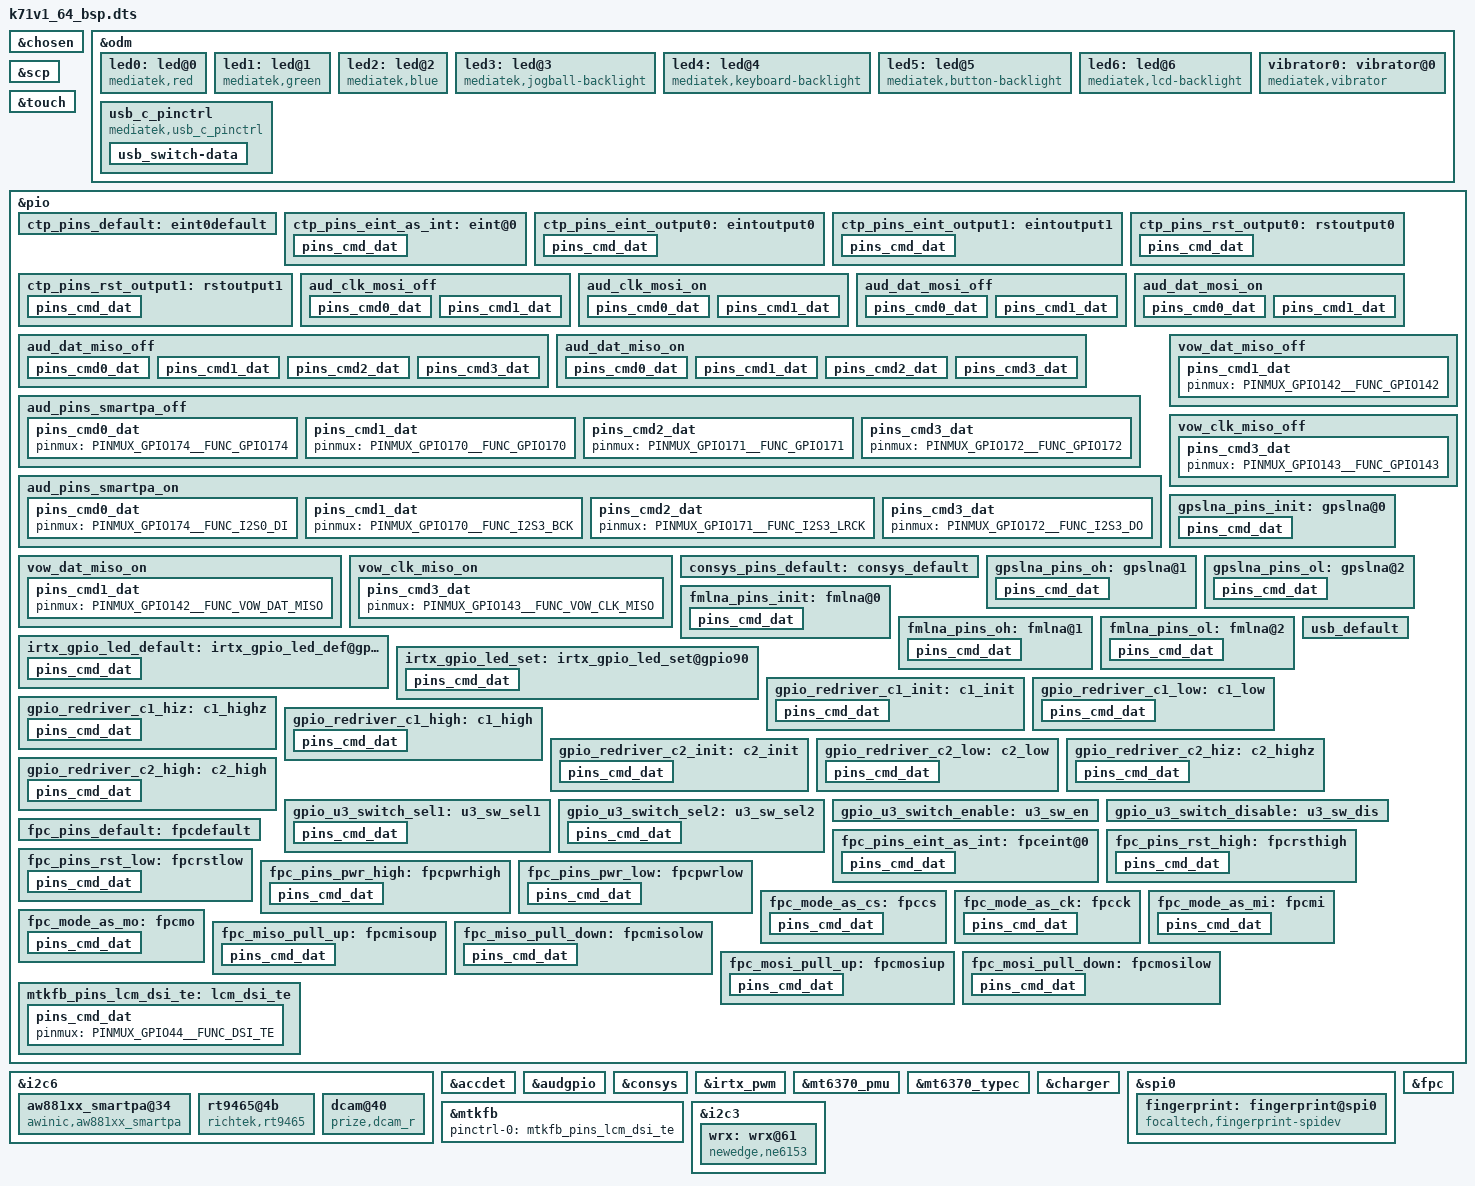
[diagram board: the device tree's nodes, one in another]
/*
 * Mediatek's mt6771 SoC device tree source
 *
 * Copyright (C) 2016 MediaTek Inc.
 *
 * This program is free software; you can redistribute it and/or modify
 * it under the terms of the GNU General Public License version 2 as
 * published by the Free Software Foundation.
 *
 * This program is distributed in the hope that it will be useful,
 * but WITHOUT ANY WARRANTY; without even the implied warranty of
 * MERCHANTABILITY or FITNESS FOR A PARTICULAR PURPOSE.
 * See http://www.gnu.org/licenses/gpl-2.0.html for more details.
 */
/dts-v1/;
/plugin/;
#include <dt-bindings/interrupt-controller/irq.h>
#include <dt-bindings/interrupt-controller/arm-gic.h>
#include <dt-bindings/pinctrl/mt6771-pinfunc.h>

/* chosen */
&chosen {
	/* fpga may has no lk, we need to specify display info here */
	/* fb buffer is reserved using this dts by memory node above */

	atag,videolfb-fb_base_l = <0x5e605000>;
	atag,videolfb-fb_base_h = <0x0>;
	atag,videolfb-islcmfound = <1>;
	atag,videolfb-islcm_inited = <0>;
	atag,videolfb-fps= <6000>;
	atag,videolfb-vramSize= <0x017bb000>;
	atag,videolfb-lcmname= "nt35595_fhd_dsi_cmd_truly_nt50358_drv";
};

&odm {
	led0:led@0 {
		compatible = "mediatek,red";
		led_mode = <0>;
		data = <1>;
		pwm_config = <0 0 0 0 0>;
	};
	led1:led@1 {
		compatible = "mediatek,green";
		led_mode = <0>;
		data = <1>;
		pwm_config = <0 0 0 0 0>;
	};
	led2:led@2 {
		compatible = "mediatek,blue";
		led_mode = <0>;
		data = <1>;
		pwm_config = <0 0 0 0 0>;
	};
	led3:led@3 {
		compatible = "mediatek,jogball-backlight";
		led_mode = <0>;
		data = <1>;
		pwm_config = <0 0 0 0 0>;
	};
	led4:led@4 {
		compatible = "mediatek,keyboard-backlight";
		led_mode = <0>;
		data = <1>;
		pwm_config = <0 0 0 0 0>;
	};
	led5:led@5 {
		compatible = "mediatek,button-backlight";
		led_mode = <0>;
		data = <1>;
		pwm_config = <0 0 0 0 0>;
	};
	led6:led@6 {
		compatible = "mediatek,lcd-backlight";
		led_mode = <5>;
		data = <1>;
		pwm_config = <0 3 0 0 0>;/*prize modify by mhy*/
	};
	vibrator0:vibrator@0 {
		compatible = "mediatek,vibrator";
		vib_timer = <25>;
		vib_limit = <9>;
		vib_vol= <11>;
	};
	usb_c_pinctrl:usb_c_pinctrl {
		compatible = "mediatek,usb_c_pinctrl";
	};
};

&scp {
	core_1 = "enable";
	scp_sramSize = <0x00080000>;     /* scp_A_sram_size */
};

/* TOUCH start */
&touch {
	tpd-resolution = <1080 2340>;/*prize modify by mhy*/
	use-tpd-button = <0>;
	tpd-key-num = <3>;
	tpd-key-local= <139 172 158 0>;
	tpd-key-dim-local = <90 883 100 40 230 883 100 40 370 883 100 40 0 0 0 0>;
	tpd-max-touch-num = <5>;
	tpd-filter-enable = <1>;
	tpd-filter-pixel-density = <146>;
	tpd-filter-custom-prameters = <0 0 0 0 0 0 0 0 0 0 0 0>;
	tpd-filter-custom-speed = <0 0 0>;
	pinctrl-names = "default", "state_eint_as_int",
		"state_eint_output0", "state_eint_output1",
		"state_rst_output0", "state_rst_output1";
	pinctrl-0 = <&ctp_pins_default>;
	pinctrl-1 = <&ctp_pins_eint_as_int>;
	pinctrl-2 = <&ctp_pins_eint_output0>;
	pinctrl-3 = <&ctp_pins_eint_output1>;
	pinctrl-4 = <&ctp_pins_rst_output0>;
	pinctrl-5 = <&ctp_pins_rst_output1>;
	status = "okay";
};
&pio {
	ctp_pins_default: eint0default {
	};
	ctp_pins_eint_as_int: eint@0 {
		pins_cmd_dat {
			pinmux = <PINMUX_GPIO1__FUNC_GPIO1>;
			slew-rate = <0>;
			bias-disable;
		};
	};
	ctp_pins_eint_output0: eintoutput0 {
		pins_cmd_dat {
			pinmux = <PINMUX_GPIO1__FUNC_GPIO1>;
			slew-rate = <1>;
			output-low;
		};
	};
	ctp_pins_eint_output1: eintoutput1 {
		pins_cmd_dat {
			pinmux = <PINMUX_GPIO1__FUNC_GPIO1>;
			slew-rate = <1>;
			output-high;
		};
	};
	ctp_pins_rst_output0: rstoutput0 {
		pins_cmd_dat {
			pinmux = <PINMUX_GPIO158__FUNC_GPIO158>;/*prize modify by mhy*/
			slew-rate = <1>;
			output-low;
		};
	};
	ctp_pins_rst_output1: rstoutput1 {
		pins_cmd_dat {
			pinmux = <PINMUX_GPIO158__FUNC_GPIO158>;/*prize modify by mhy*/
			slew-rate = <1>;
			output-high;
		};
	};
};
/* TOUCH end */
/*prize-add-xuxiaoming-20200116-start */
&i2c6 {
	aw881xx_smartpa@34 {
		compatible = "awinic,aw881xx_smartpa";
		reg = <0x34>;
		reset-gpio = <&pio 176 0>;
		irq-gpio = <&pio 173 0>;
		status = "okay";
	};
};
/*prize-add-xuxiaoming-20200116-end */
/* accdet start */
&accdet {
	/* accdet micbias voltage: 0x07,2.7v;0x05,2.5v;0x02,1.9v */
	accdet-mic-vol = <6>;
	headset-mode-setting = <0x500 0x500 1 0x1f0 0x800 0x800 0x20 0x44>;
	accdet-plugout-debounce = <1>;
	/*1:ACC mode, 2:low cost without in bias, 6:low cost with in bias*/
	accdet-mic-mode = <1>;
	/* eint_level_trigger: 8,LEVEL_LOW(default);4,LEVEL_HIGH;others,LEVEL_LOW */
	headset-eint-level-pol = <8>;
	/*0--MD_MAX--UP_MAX--DW_MAX*/
/* prize modified by lifenfen, fixbug 72141, meizu headset resistor is 185/288 less than normal, 20190313 begin */
	//headset-three-key-threshold = <0 80 220 400>;
	headset-three-key-threshold = <0 80 200 400>;
/* prize modified by lifenfen, fixbug 72141, meizu headset resistor is 185/288 less than normal, 20190313 end */
	headset-three-key-threshold-CDD = <0 121 192 600>;
	/*0--MD_MAX--VOICE_MAX--UP_MAX--DW_MAX*/
	headset-four-key-threshold = <0 58 121 192 400>;
	status = "okay";
};
/* accdet end */

/* AUDIO GPIO standardization */
&audgpio {
	pinctrl-names = "aud_clk_mosi_off",
			"aud_clk_mosi_on",
			"aud_dat_mosi_off",
			"aud_dat_mosi_on",
			"aud_dat_miso_off",
			"aud_dat_miso_on",
			"aud_smartpa_off",
			"aud_smartpa_on",
			"vow_dat_miso_off",
			"vow_dat_miso_on",
			"vow_clk_miso_off",
			"vow_clk_miso_on";
	pinctrl-0 = <&aud_clk_mosi_off>;
	pinctrl-1 = <&aud_clk_mosi_on>;
	pinctrl-2 = <&aud_dat_mosi_off>;
	pinctrl-3 = <&aud_dat_mosi_on>;
	pinctrl-4 = <&aud_dat_miso_off>;
	pinctrl-5 = <&aud_dat_miso_on>;
	pinctrl-6 = <&aud_pins_smartpa_off>;
	pinctrl-7 = <&aud_pins_smartpa_on>;
	pinctrl-8 = <&vow_dat_miso_off>;
	pinctrl-9 = <&vow_dat_miso_on>;
	pinctrl-10 = <&vow_clk_miso_off>;
	pinctrl-11 = <&vow_clk_miso_on>;
	status = "okay";
};

&pio {
	aud_clk_mosi_off: aud_clk_mosi_off {
		pins_cmd0_dat {
			pinmux = <PINMUX_GPIO136__FUNC_GPIO136>;
			input-enable;
			slew-rate = <0>;
			bias-disable;
		};
		pins_cmd1_dat {
			pinmux = <PINMUX_GPIO137__FUNC_GPIO137>;
			input-enable;
			slew-rate = <0>;
			bias-disable;
		};
	};

	aud_clk_mosi_on: aud_clk_mosi_on {
		pins_cmd0_dat {
			pinmux = <PINMUX_GPIO136__FUNC_AUD_CLK_MOSI>;
			input-schmitt-enable;
		};
		pins_cmd1_dat {
			pinmux = <PINMUX_GPIO137__FUNC_AUD_SYNC_MOSI>;
			input-schmitt-enable;
		};
	};

	aud_dat_mosi_off: aud_dat_mosi_off {
		pins_cmd0_dat {
			pinmux = <PINMUX_GPIO138__FUNC_GPIO138>;
			input-enable;
			slew-rate = <0>;
			bias-disable;
		};
		pins_cmd1_dat {
			pinmux = <PINMUX_GPIO139__FUNC_GPIO139>;
			input-enable;
			slew-rate = <0>;
			bias-pull-down;
		};
	};

	aud_dat_mosi_on: aud_dat_mosi_on {
		pins_cmd0_dat {
			pinmux = <PINMUX_GPIO138__FUNC_AUD_DAT_MOSI0>;
			input-schmitt-enable;
		};
		pins_cmd1_dat {
			pinmux = <PINMUX_GPIO139__FUNC_AUD_DAT_MOSI1>;
			input-schmitt-enable;
		};
	};

	aud_dat_miso_off: aud_dat_miso_off {
		pins_cmd0_dat {
			pinmux = <PINMUX_GPIO140__FUNC_GPIO140>;
			input-enable;
			slew-rate = <0>;
			bias-disable;
		};
		pins_cmd1_dat {
			pinmux = <PINMUX_GPIO141__FUNC_GPIO141>;
			input-enable;
			slew-rate = <0>;
			bias-disable;
		};
		pins_cmd2_dat {
			pinmux = <PINMUX_GPIO142__FUNC_GPIO142>;
			input-enable;
			slew-rate = <0>;
			bias-disable;
		};
		pins_cmd3_dat {
			pinmux = <PINMUX_GPIO143__FUNC_GPIO143>;
			input-enable;
			slew-rate = <0>;
			bias-disable;
		};
	};

	aud_dat_miso_on: aud_dat_miso_on {
		pins_cmd0_dat {
			pinmux = <PINMUX_GPIO140__FUNC_AUD_CLK_MISO>;
			input-schmitt-enable;
		};
		pins_cmd1_dat {
			pinmux = <PINMUX_GPIO141__FUNC_AUD_SYNC_MISO>;
			input-schmitt-enable;
		};
		pins_cmd2_dat {
			pinmux = <PINMUX_GPIO142__FUNC_AUD_DAT_MISO0>;
			input-schmitt-enable;
		};
		pins_cmd3_dat {
			pinmux = <PINMUX_GPIO143__FUNC_AUD_DAT_MISO1>;
			input-schmitt-enable;
		};
	};

	aud_pins_smartpa_off: aud_pins_smartpa_off {
		pins_cmd0_dat {
			pinmux = <PINMUX_GPIO174__FUNC_GPIO174>;
		};
		pins_cmd1_dat {
			pinmux = <PINMUX_GPIO170__FUNC_GPIO170>;
		};
		pins_cmd2_dat {
			pinmux = <PINMUX_GPIO171__FUNC_GPIO171>;
		};
		pins_cmd3_dat {
			pinmux = <PINMUX_GPIO172__FUNC_GPIO172>;
		};
	};

	aud_pins_smartpa_on: aud_pins_smartpa_on {
		pins_cmd0_dat {
			pinmux = <PINMUX_GPIO174__FUNC_I2S0_DI>;
		};
		pins_cmd1_dat {
			pinmux = <PINMUX_GPIO170__FUNC_I2S3_BCK>;
		};
		pins_cmd2_dat {
			pinmux = <PINMUX_GPIO171__FUNC_I2S3_LRCK>;
		};
		pins_cmd3_dat {
			pinmux = <PINMUX_GPIO172__FUNC_I2S3_DO>;
		};
	};

	vow_dat_miso_off: vow_dat_miso_off {
		pins_cmd1_dat {
			pinmux = <PINMUX_GPIO142__FUNC_GPIO142>;
		};
	};

	vow_dat_miso_on: vow_dat_miso_on {
		pins_cmd1_dat {
			pinmux = <PINMUX_GPIO142__FUNC_VOW_DAT_MISO>;
		};
	};

	vow_clk_miso_off: vow_clk_miso_off {
		pins_cmd3_dat {
			pinmux = <PINMUX_GPIO143__FUNC_GPIO143>;
		};
	};

	vow_clk_miso_on: vow_clk_miso_on {
		pins_cmd3_dat {
			pinmux = <PINMUX_GPIO143__FUNC_VOW_CLK_MISO>;
		};
	};
};
/* AUDIO end */

/* CONSYS GPIO standardization */
&pio {
	consys_pins_default: consys_default {
	};
	gpslna_pins_init: gpslna@0 {
		pins_cmd_dat {
			pinmux = <PINMUX_GPIO155__FUNC_GPIO155>;
			slew-rate = <0>;
			bias-disable;
			output-low;
		};
	};
	gpslna_pins_oh: gpslna@1 {
		pins_cmd_dat {
			pinmux = <PINMUX_GPIO155__FUNC_GPIO155>;
			slew-rate = <1>;
			output-high;
		};
	};
	gpslna_pins_ol: gpslna@2 {
		pins_cmd_dat {
			pinmux = <PINMUX_GPIO155__FUNC_GPIO155>;
			slew-rate = <1>;
			output-low;
		};
	};
	/*prize add by mhy start*/
	fmlna_pins_init: fmlna@0 {
		pins_cmd_dat {
			pinmux = <PINMUX_GPIO160__FUNC_GPIO160>;
			slew-rate = <0>;
			bias-disable;
			output-low;
		};
	};
	fmlna_pins_oh: fmlna@1 {
		pins_cmd_dat {
			pinmux = <PINMUX_GPIO160__FUNC_GPIO160>;
			slew-rate = <1>;
			output-high;
		};
	};
	fmlna_pins_ol: fmlna@2 {
		pins_cmd_dat {
			pinmux = <PINMUX_GPIO160__FUNC_GPIO160>;
			slew-rate = <1>;
			output-low;
		};
	};
	/*prize add by mhy end*/
};
&consys {
	pinctrl-names = "default", "gps_lna_state_init", "gps_lna_state_oh", "gps_lna_state_ol",/*prize modify by mhy start*/
	"fm_lna_state_init", "fm_lna_state_oh", "fm_lna_state_ol";/*prize add by mhy*/
	pinctrl-0 = <&consys_pins_default>;
	pinctrl-1 = <&gpslna_pins_init>;
	pinctrl-2 = <&gpslna_pins_oh>;
	pinctrl-3 = <&gpslna_pins_ol>;
	/*prize add by mhy start*/
        pinctrl-4 = <&fmlna_pins_init>;
        pinctrl-5 = <&fmlna_pins_oh>;
        pinctrl-6 = <&fmlna_pins_ol>;
	/*prize add by mhy end*/
	status = "okay";
};
/* CONSYS end */

/* IRTX GPIO Start */
&irtx_pwm {
	pinctrl-names = "irtx_gpio_led_default", "irtx_gpio_led_set";
	pinctrl-0 = <&irtx_gpio_led_default>;
	pinctrl-1 = <&irtx_gpio_led_set>;
	status = "okay";
};
&pio {
	/* IRTX GPIO Settings -Start */
	/* default: GPIO0, output, high */
	irtx_gpio_led_default:irtx_gpio_led_def@gpio90 {
		pins_cmd_dat {
			pinmux = <PINMUX_GPIO90__FUNC_GPIO90>;
			slew-rate = <1>;
			bias-disable;
			output-low;
			input-schmitt-enable = <0>;
		};
	};

	irtx_gpio_led_set:irtx_gpio_led_set@gpio90 {
		pins_cmd_dat {
			pinmux = <PINMUX_GPIO90__FUNC_PWM_A>;
			slew-rate = <1>;
			output-high;
		};
	};
}; /* IRTX GPIO Settings -End */

&mt6370_pmu {
	mt6370,intr_gpio_num = <10>; /* direct defined GPIO num */
	mt6370,intr_gpio = <&pio 10 0x0>;
};

&mt6370_typec {
	mt6370pd,intr_gpio_num = <41>; /* direct defined GPIO num */
	mt6370pd,intr_gpio = <&pio 41 0x0>;
};

/* USB TYPEC GPIO start */
&pio {
	usb_default: usb_default {
	};

	gpio_redriver_c1_init: c1_init {
		pins_cmd_dat {
			pinmux = <PINMUX_GPIO18__FUNC_GPIO18>;
			slew-rate = <1>;
			output-low;
		};
	};

	gpio_redriver_c1_low: c1_low {
		pins_cmd_dat {
			pinmux = <PINMUX_GPIO18__FUNC_GPIO18>;
			slew-rate = <1>;
			output-low;
		};
	};

	gpio_redriver_c1_hiz: c1_highz {
		pins_cmd_dat {
			pinmux = <PINMUX_GPIO18__FUNC_GPIO18>;
			slew-rate= <0>;
			bias-disable;
		};
	};

	gpio_redriver_c1_high: c1_high {
		pins_cmd_dat {
			pinmux = <PINMUX_GPIO18__FUNC_GPIO18>;
			slew-rate = <1>;
			output-high;
		};
	};

	gpio_redriver_c2_init: c2_init {
		pins_cmd_dat {
			pinmux = <PINMUX_GPIO17__FUNC_GPIO17>;
			slew-rate = <1>;
			output-low;
		};
	};

	gpio_redriver_c2_low: c2_low {
		pins_cmd_dat {
			pinmux = <PINMUX_GPIO17__FUNC_GPIO17>;
			slew-rate = <1>;
			output-low;
		};
	};

	gpio_redriver_c2_hiz: c2_highz {
		pins_cmd_dat {
			pinmux = <PINMUX_GPIO17__FUNC_GPIO17>;
			slew-rate= <0>;
			bias-disable;
		};
	};

	gpio_redriver_c2_high: c2_high {
		pins_cmd_dat {
			pinmux = <PINMUX_GPIO17__FUNC_GPIO17>;
			slew-rate = <1>;
			output-high;
		};
	};

	gpio_u3_switch_sel1: u3_sw_sel1 {
		pins_cmd_dat {
			pinmux = <PINMUX_GPIO177__FUNC_GPIO177>;
			slew-rate = <1>;
			output-low;
		};
	};

	gpio_u3_switch_sel2: u3_sw_sel2 {
		pins_cmd_dat {
			pinmux = <PINMUX_GPIO177__FUNC_GPIO177>;
			slew-rate = <1>;
			output-high;
		};
	};

	gpio_u3_switch_enable: u3_sw_en {
	};

	gpio_u3_switch_disable: u3_sw_dis {
	};
};

&usb_c_pinctrl {
	pinctrl-names = "usb_default",
		"redrv_c1_init",
		"redrv_c1_low",
		"redrv_c1_hiz",
		"redrv_c1_high",
		"redrv_c2_init",
		"redrv_c2_low",
		"redrv_c2_hiz",
		"redrv_c2_high",
		"switch_sel1",
		"switch_sel2",
		"switch_enable",
		"switch_disable";

	pinctrl-0 = <&usb_default>;
	pinctrl-1 = <&gpio_redriver_c1_init>;
	pinctrl-2 = <&gpio_redriver_c1_low>;
	pinctrl-3 = <&gpio_redriver_c1_hiz>;
	pinctrl-4 = <&gpio_redriver_c1_high>;
	pinctrl-5 = <&gpio_redriver_c2_init>;
	pinctrl-6 = <&gpio_redriver_c2_low>;
	pinctrl-7 = <&gpio_redriver_c2_hiz>;
	pinctrl-8 = <&gpio_redriver_c2_high>;
	pinctrl-9 = <&gpio_u3_switch_sel1>;
	pinctrl-10 = <&gpio_u3_switch_sel2>;
	pinctrl-11 = <&gpio_u3_switch_enable>;
	pinctrl-12 = <&gpio_u3_switch_disable>;
	status = "okay";

	usb_switch-data {
		en_pin_num = <0>;
		en_pin_val = <0>; /*DISABLE=0 ENABLE=1*/
		sel_pin_num = <177>;
		sel_pin_val = <1>; /*CC1=1, CC2=2*/
		c1_pin_num = <18>;
		c1_pin_val = <2>; /*Low=0, HighZ=1, High=2*/
		c2_pin_num = <17>;
		c2_pin_val = <1>;
	};
};
/* USB TYPEC GPIO end */

&charger {
	algorithm_name = "DualSwitchCharging";
	battery_cv = <4400000>;
	chg1_ta_ac_charger_current = <1400000>;/*prize-sunshuai-20190429, modify master charge battery charge limit*/
	chg2_ta_ac_charger_current = <1100000>;/*prize-sunshuai-20190429, modify slave charge battery charge limit*/
	min_charge_temp = <(1)>;     //prize-mod sunshuai 20190307 modify a low temp threshold
	min_charge_temp_plus_x_degree = <3>;  //prize-mod sunshuai 20190307 modify a low temp threshold exit
	max_charge_temp = <50>;  //prize-mod wyq 20181121 modify a higher temp threshold
	max_charge_temp_minus_x_degree = <48>;  //prize-mod wyq 20181121 modify a higher temp threshold
};

&i2c6 {
	rt9465@4b {
		compatible = "richtek,rt9465";
		reg = <0x4b>;
		status = "okay";
		rt,en_gpio_num = <92>;/*prize modify by mhy*/
		rt,en_gpio = <&pio 92 0x0>;/*prize modify by mhy*/
		rt,intr_gpio_num = <69>; /* prize modify by mhy direct defined GPIO num */
		rt,intr_gpio = <&pio 69 0x0>;/*prize modify by mhy*/
		interrupt-names = "wdtmri";
		charger_name = "secondary_chg";
		ichg = <1500000>; /* uA */
		mivr = <4500000>; /* uV */
		cv = <4550000>; /* uV */
		ieoc = <700000>; /* uA */
		safety_timer = <12>; /* hour */
		en_st; /* safety timer */
		/* en_te; */
		en_wdt;
	};
};

/* prize-add-pengzhipeng-20191011-start */
&spi0{
	#address-cells = <1>;
	#size-cells = <0>;
	fingerprint: fingerprint@spi0{
		compatible = "focaltech,fingerprint-spidev";
		reg = <0>;
		spi-max-frequency = <1000000>;
		status = "okay";
	};
};
&fpc {

	interrupt-parent = <&pio>;
	interrupts = <0 IRQ_TYPE_EDGE_FALLING 0 0>;	
	pinctrl-names = "default",
		"fpc_eint_as_int",
		"fpc_pins_rst_high", "fpc_pins_rst_low",
		"fpc_pins_pwr_high", "fpc_pins_pwr_low",
		"fpc_mode_as_cs", "fpc_mode_as_ck",
		"fpc_mode_as_mi", "fpc_mode_as_mo",
		"fpc_miso_pull_up", "fpc_miso_pull_down",
		"fpc_mosi_pull_up", "fpc_mosi_pull_down";
	pinctrl-0 = <&fpc_pins_default>;
	pinctrl-1 = <&fpc_pins_eint_as_int>;
	pinctrl-2 = <&fpc_pins_rst_high>;
	pinctrl-3 = <&fpc_pins_rst_low>;
	pinctrl-4 = <&fpc_pins_pwr_high>;
	pinctrl-5 = <&fpc_pins_pwr_low>;
	pinctrl-6 = <&fpc_mode_as_cs>;
	pinctrl-7 = <&fpc_mode_as_ck>;
	pinctrl-8= <&fpc_mode_as_mi>;
	pinctrl-9 = <&fpc_mode_as_mo>;
	pinctrl-10 = <&fpc_miso_pull_up>;
	pinctrl-11 = <&fpc_miso_pull_down>;
	pinctrl-12 = <&fpc_mosi_pull_up>;
	pinctrl-13 = <&fpc_mosi_pull_down>;
	status = "okay";
};

&pio {
	fpc_pins_default: fpcdefault {
	};

	fpc_pins_eint_as_int: fpceint@0 {
		pins_cmd_dat {
			pinmux = <PINMUX_GPIO0__FUNC_GPIO0>;
			slew-rate = <0>;
			bias-disable;
		};
	};
	fpc_pins_rst_high: fpcrsthigh {
		pins_cmd_dat {
			pinmux = <PINMUX_GPIO175__FUNC_GPIO175>;
			slew-rate = <1>;
			output-high;
		};
	};
	fpc_pins_rst_low: fpcrstlow {
		pins_cmd_dat {
			pinmux = <PINMUX_GPIO175__FUNC_GPIO175>;
			slew-rate = <1>;
			output-low;
		};
	};
	fpc_pins_pwr_high: fpcpwrhigh {
		pins_cmd_dat {
			pinmux = <PINMUX_GPIO80__FUNC_GPIO80>;
			slew-rate = <1>;
			output-high;
		};
	};
	fpc_pins_pwr_low: fpcpwrlow {
		pins_cmd_dat {
			pinmux = <PINMUX_GPIO80__FUNC_GPIO80>;
			slew-rate = <1>;
			output-low;
		};
	};	
	fpc_mode_as_cs: fpccs {
		pins_cmd_dat {
			pinmux = <PINMUX_GPIO86__FUNC_SPI0_CSB>;
			bias-pull-up = <00>;
		};
	};
	fpc_mode_as_ck: fpcck {
		pins_cmd_dat {
			pinmux = <PINMUX_GPIO88__FUNC_SPI0_CLK>;
			bias-pull-up = <00>;
		};
	};
	fpc_mode_as_mi: fpcmi {
		pins_cmd_dat {
			pinmux = <PINMUX_GPIO85__FUNC_SPI0_MI>;
			bias-pull-up = <00>;
		};
	};
	fpc_mode_as_mo: fpcmo {
		pins_cmd_dat {
			pinmux = <PINMUX_GPIO87__FUNC_SPI0_MO>;
			bias-pull-down = <00>;
		};
	};
	fpc_miso_pull_up: fpcmisoup {
		pins_cmd_dat {
			pinmux = <PINMUX_GPIO85__FUNC_GPIO85>;
			slew-rate = <1>;
			output-high;
		};
	};
	fpc_miso_pull_down: fpcmisolow {
		pins_cmd_dat {
			pinmux = <PINMUX_GPIO85__FUNC_GPIO85>;
			slew-rate = <1>;
			output-low;
		};
	};
	fpc_mosi_pull_up: fpcmosiup {
		pins_cmd_dat {
			pinmux = <PINMUX_GPIO87__FUNC_GPIO87>;
			slew-rate = <1>;
			output-high;
		};
	};
	fpc_mosi_pull_down: fpcmosilow {
		pins_cmd_dat {
			pinmux = <PINMUX_GPIO87__FUNC_GPIO87>;
			slew-rate = <1>;
			output-low;
		};
	};
};
/* prize-add-pengzhipeng-20191011-end */
&pio {
	mtkfb_pins_lcm_dsi_te: lcm_dsi_te {
		pins_cmd_dat {
			pinmux = <PINMUX_GPIO44__FUNC_DSI_TE>;
		};
	};
};

&mtkfb {
	pinctrl-names = "mode_te_te";
	pinctrl-0 = <&mtkfb_pins_lcm_dsi_te>;
	status = "okay";
};
/*start prize-sunshuai-20190126, add for Wireless NE6153 support  */
&i2c3 {
	wrx: wrx@61 {
		compatible = "newedge,ne6153";
		reg = <0x61>;
/* prize-add-pengzhipeng-20191016-start */
		en-gpio = <&pio 17 0>;
/* prize-add-pengzhipeng-20191016-end */
		wrx_irq_debounce = <256000>;
		};
};
/*prize add by zhuzhengjiang for dcam  20200316 start*/
&i2c6 {
	dcam@40 {
		compatible = "prize,dcam_r";
		reg = <0x3c>;
		pdn_pin = <&pio 169 0>;
		rst_pin = <&pio 179 0>;
		sensor_type = <6133>;	/*DO NOT write 0310*/
	};
};
/*prize add by zhuzhengjiang for dcam  20200316 end*/
#include <k71v1_64_bsp/cust.dtsi>
#include "cust_mt6771_camera.dtsi"
/*End of this file, DO NOT ADD ANYTHING HERE*/


